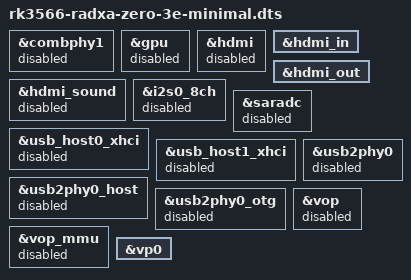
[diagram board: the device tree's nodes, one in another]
#include "rk3566-radxa-zero-3e.dts"

/ {
	/delete-node/ hdmi-con;
};


&combphy1 {
	status = "disabled";
};

&gpu {
	status = "disabled";
};

&hdmi {
	status = "disabled";
};

&hdmi_in {
	/delete-node/ endpoint;
};

&hdmi_out {
	/delete-node/ endpoint;
};

&hdmi_sound {
	status = "disabled";
};

&i2s0_8ch {
	status = "disabled";
};

&saradc {
	status = "disabled";
};

&usb_host0_xhci {
	status = "disabled";
};

&usb_host1_xhci {
	status = "disabled";
};

&usb2phy0 {
	status = "disabled";
};

&usb2phy0_host {
	status = "disabled";
};

&usb2phy0_otg {
	status = "disabled";
};

&vop {
	status = "disabled";
};

&vop_mmu {
	status = "disabled";
};

&vp0 {
	/delete-node/ endpoint@ROCKCHIP_VOP2_EP_HDMI0;
};
